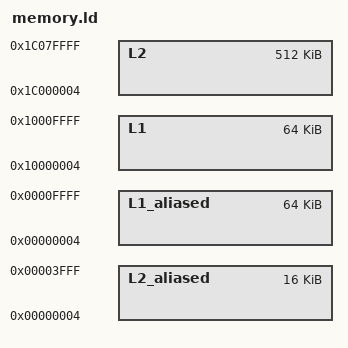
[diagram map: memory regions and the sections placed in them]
PROVIDE(__boot_address = 0x1c000880);
MEMORY
{
  L2           : ORIGIN = 0x1c000004, LENGTH = 0x0007fffc
  L2_aliased   : ORIGIN = 0x00000004, LENGTH = 0x00003ffc
  L1           : ORIGIN = 0x10000004, LENGTH = 0x0000fffc
  L1_aliased   : ORIGIN = 0x00000004, LENGTH = 0x0000fffc
}



REGION_ALIAS("REGION_TEXT", L2);
REGION_ALIAS("REGION_RODATA", L2);
REGION_ALIAS("REGION_DATA", L2);
REGION_ALIAS("REGION_BSS", L2);
REGION_ALIAS("REGION_HEAP", L2);
REGION_ALIAS("REGION_STACK", L2);

